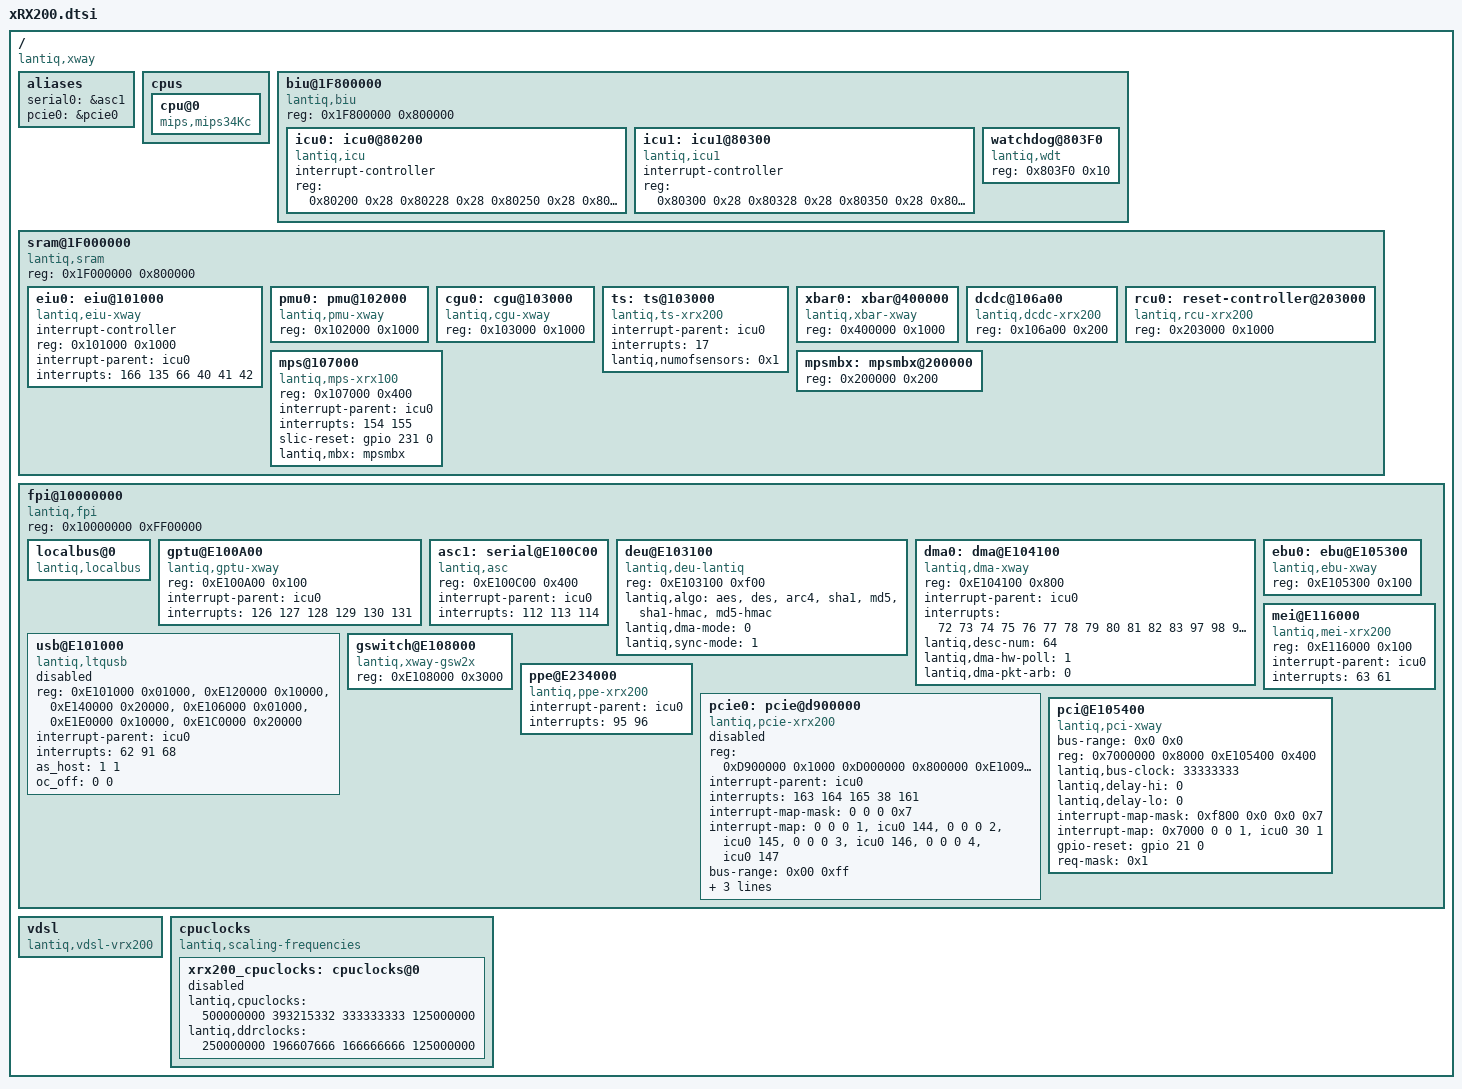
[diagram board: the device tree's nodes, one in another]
/ {
	#address-cells = <1>;
	#size-cells = <1>;
	compatible = "lantiq,xway", "lantiq,vr9";

	aliases {
		serial0 = &asc1;
		pcie0   = &pcie0;
	};

	cpus {
		cpu@0 {
			compatible = "mips,mips34Kc";
		};
	};

	biu@1F800000 {
		#address-cells = <1>;
		#size-cells = <1>;
		compatible = "lantiq,biu", "simple-bus";
		reg = <0x1F800000 0x800000>;
		ranges = <0x0 0x1F800000 0x7FFFFF>;

		icu0: icu0@80200 {
			#interrupt-cells = <1>;
			interrupt-controller;
			compatible = "lantiq,icu";
			reg = <0x80200 0x28
				0x80228 0x28
				0x80250 0x28
				0x80278 0x28
				0x802a0 0x28>;
		};

		icu1: icu1@80300 {
			#interrupt-cells = <1>;
			interrupt-controller;
			compatible = "lantiq,icu1";
			reg = <0x80300 0x28
				0x80328 0x28
				0x80350 0x28
				0x80378 0x28
				0x803a0 0x28>;
		};

		watchdog@803F0 {
			compatible = "lantiq,wdt";
			reg = <0x803F0 0x10>;
		};
	};

	sram@1F000000 {
		#address-cells = <1>;
		#size-cells = <1>;
		compatible = "lantiq,sram", "simple-bus";
		reg = <0x1F000000 0x800000>;
		ranges = <0x0 0x1F000000 0x7FFFFF>;

		eiu0: eiu@101000 {
			#interrupt-cells = <1>;
			interrupt-controller;
			compatible = "lantiq,eiu-xway";
			reg = <0x101000 0x1000>;
			interrupt-parent = <&icu0>;
			interrupts = <166 135 66 40 41 42>;
		};

		pmu0: pmu@102000 {
			compatible = "lantiq,pmu-xway";
			reg = <0x102000 0x1000>;
		};

		cgu0: cgu@103000 {
			compatible = "lantiq,cgu-xway";
			reg = <0x103000 0x1000>;
		};

		ts: ts@103000 {
			compatible = "lantiq,ts-xrx200";
			interrupt-parent = <&icu0>;
			interrupts = <17>;
			lantiq,numofsensors = <0x1>;
		};

		xbar0: xbar@400000 {
			compatible = "lantiq,xbar-xway";
			reg = <0x400000 0x1000>;
		};

		dcdc@106a00 {
			compatible = "lantiq,dcdc-xrx200";
			reg = <0x106a00 0x200>;
		};

		rcu0: reset-controller@203000 {
			compatible = "lantiq,rcu-xrx200";
			reg = <0x203000 0x1000>;
			#reset-cells = <1>; 
		};

		mps@107000 {
			compatible = "lantiq,mps-xrx100";
			reg = <0x107000 0x400>;
			interrupt-parent = <&icu0>;
			interrupts = <154 155>;
			slic-reset = <&gpio 231 0>;
			lantiq,mbx = <&mpsmbx>;
		};

		mpsmbx: mpsmbx@200000 {
			reg = <0x200000 0x200>;
		};
	};

	fpi@10000000 {
		#address-cells = <1>;
		#size-cells = <1>;
		compatible = "lantiq,fpi", "simple-bus";
		ranges = <0x0 0x10000000 0xFFFFFFF>;
		reg = <0x10000000 0xFF00000>;

		localbus@0 {
			#address-cells = <2>;
			#size-cells = <1>;
			ranges = <0 0 0x0 0x3ffffff /* addrsel0 */
				1 0 0x4000000 0x4000010>; /* addsel1 */
			compatible = "lantiq,localbus", "simple-bus";
		};

		gptu@E100A00 {
			compatible = "lantiq,gptu-xway";
			reg = <0xE100A00 0x100>;
			interrupt-parent = <&icu0>;
			interrupts = <126 127 128 129 130 131>;
		};

		asc1: serial@E100C00 {
			compatible = "lantiq,asc";
			reg = <0xE100C00 0x400>;
			interrupt-parent = <&icu0>;
			interrupts = <112 113 114>;
		};

		deu@E103100 {
			compatible = "lantiq,deu-lantiq";
			reg = <0xE103100 0xf00>;
			lantiq,algo = "aes", "des", "arc4", "sha1", "md5", "sha1-hmac", "md5-hmac";
			lantiq,dma-mode = <0>;
			lantiq,sync-mode = <1>;
		};

		dma0: dma@E104100 {
			compatible = "lantiq,dma-xway";
			reg = <0xE104100 0x800>;
			interrupt-parent = <&icu0>;
			interrupts = <72 73 74 75 76 77 78 79 80 81 82 83 97 98 99 100 101 70 88 93 136 137 138 139 140 141 142 143>;
			lantiq,desc-num = <64>;
			lantiq,dma-hw-poll = <1>;
			lantiq,dma-pkt-arb = <0>;
		};

		ebu0: ebu@E105300 {
			compatible = "lantiq,ebu-xway";
			reg = <0xE105300 0x100>;
		};

		usb@E101000 {
			compatible = "lantiq,ltqusb";
			reg = <0xE101000 0x01000>,
				<0xE120000 0x10000>,
				<0xE140000 0x20000>,
				<0xE106000 0x01000>,
				<0xE1E0000 0x10000>,
				<0xE1C0000 0x20000>;
			interrupt-parent = <&icu0>;

			interrupts = <62 91 68>; /* interrupt content is USB1 USB2 OC */
			as_host    = <1 1>;
			oc_off     = <0 0>;
			status = "disabled";
		};

		mei@E116000 {
			compatible = "lantiq,mei-xrx200";
			reg = <0xE116000 0x100>;
			interrupt-parent = <&icu0>;
			interrupts = <63 61>;
		};

		gswitch@E108000 {
			#address-cells = <1>;
			#size-cells = <0>;
			compatible = "lantiq,xway-gsw2x"; /*GSW2X SWAPI */
			reg = <0xE108000 0x3000>;
		};

		ppe@E234000 {
			compatible = "lantiq,ppe-xrx200";
			interrupt-parent = <&icu0>;
			interrupts = <95 96>;
		};

		pcie0:pcie@d900000 {
			status = "disabled";
			compatible = "lantiq,pcie-xrx200";
			device_type = "pci";
			#address-cells = <3>;
			#size-cells = <2>;
			reg = < 0xD900000 0x1000 /* RC controller */
				0xD000000 0x800000 /* Cfg Space */
				0xE100900 0x100 /* App logic */
				0xF106800 0x200 /* PCIe PHY Reg */
				0xF600000 0x100000 /* MSI addr space */
				0xF700000 0x400 /* MSI PIC */
			>;
			reg-names = "csr", "cfg", "app", "phy", "msi", "pic";
			interrupt-parent = <&icu0>;
			interrupts = <163 164 165 38 161>;
			interrupt-names = "msi0", "msi1", "msi2", "msi3", "ir";
			#interrupt-cells = <1>;
			interrupt-map-mask = <0 0 0 0x7>;
			interrupt-map = <0 0 0 1 &icu0  144>,
					<0 0 0 2 &icu0  145>,
					<0 0 0 3 &icu0  146>,
					<0 0 0 4 &icu0  147>;
			bus-range = <0x00 0xff>;
			ranges = <0x02000000 0 0x0C000000 0x0C000000 0 0x01000000    /* Non-pretechable memory 32bit */
				  0x01000000 0 0x0D800000 0x0D800000 0 0x00100000    /* Downsream I/O */ 
				 >;  
			resets = <&rcu0 12>,
				 <&rcu0 22>; 
			reset-names = "phy", "core", "inbound", "outbound";
			lantiq,inbound-shift = <0>;
			lantiq,outbound-shift = <4>;
		};

		pci@E105400 {
			#address-cells = <3>;
			#size-cells = <2>;
			#interrupt-cells = <1>;
			compatible = "lantiq,pci-xway", "lantiq,pci-boot-xrx200";
			bus-range = <0x0 0x0>;
			ranges = <0x2000000 0 0x8000000 0x8000000 0 0x2000000 /* pci memory */
				0x1000000 0 0x00000000 0xAE00000 0 0x200000>; /* io space */
			reg = <0x7000000 0x8000         /* config space */
				0xE105400 0x400>;       /* pci bridge */
			lantiq,bus-clock = <33333333>; /*lantiq,bus-clock = <62500000>; for bonding */
			/*lantiq,external-clock;*/
			lantiq,delay-hi = <0>; /* 0ns delay for non-bonding case, 6 for bonding  */
			lantiq,delay-lo = <0>; /* 0.0ns delay */
			interrupt-map-mask = <0xf800 0x0 0x0 0x7>;
			interrupt-map = <
				0x7000 0 0 1 &icu0 30 1 // slot 14, irq 29
				>;
			gpio-reset = <&gpio 21 0>;
			req-mask = <0x1>;	/* One external master  */
		};
	};

	vdsl {
		compatible = "lantiq,vdsl-vrx200";
	};

	cpuclocks {
		compatible = "lantiq,scaling-frequencies";

		xrx200_cpuclocks: cpuclocks@0 {
			status = "disabled";
			lantiq,cpuclocks = <500000000 393215332 333333333 125000000>;
			lantiq,ddrclocks = <250000000 196607666 166666666 125000000>;
		}; 
	}; 
};
